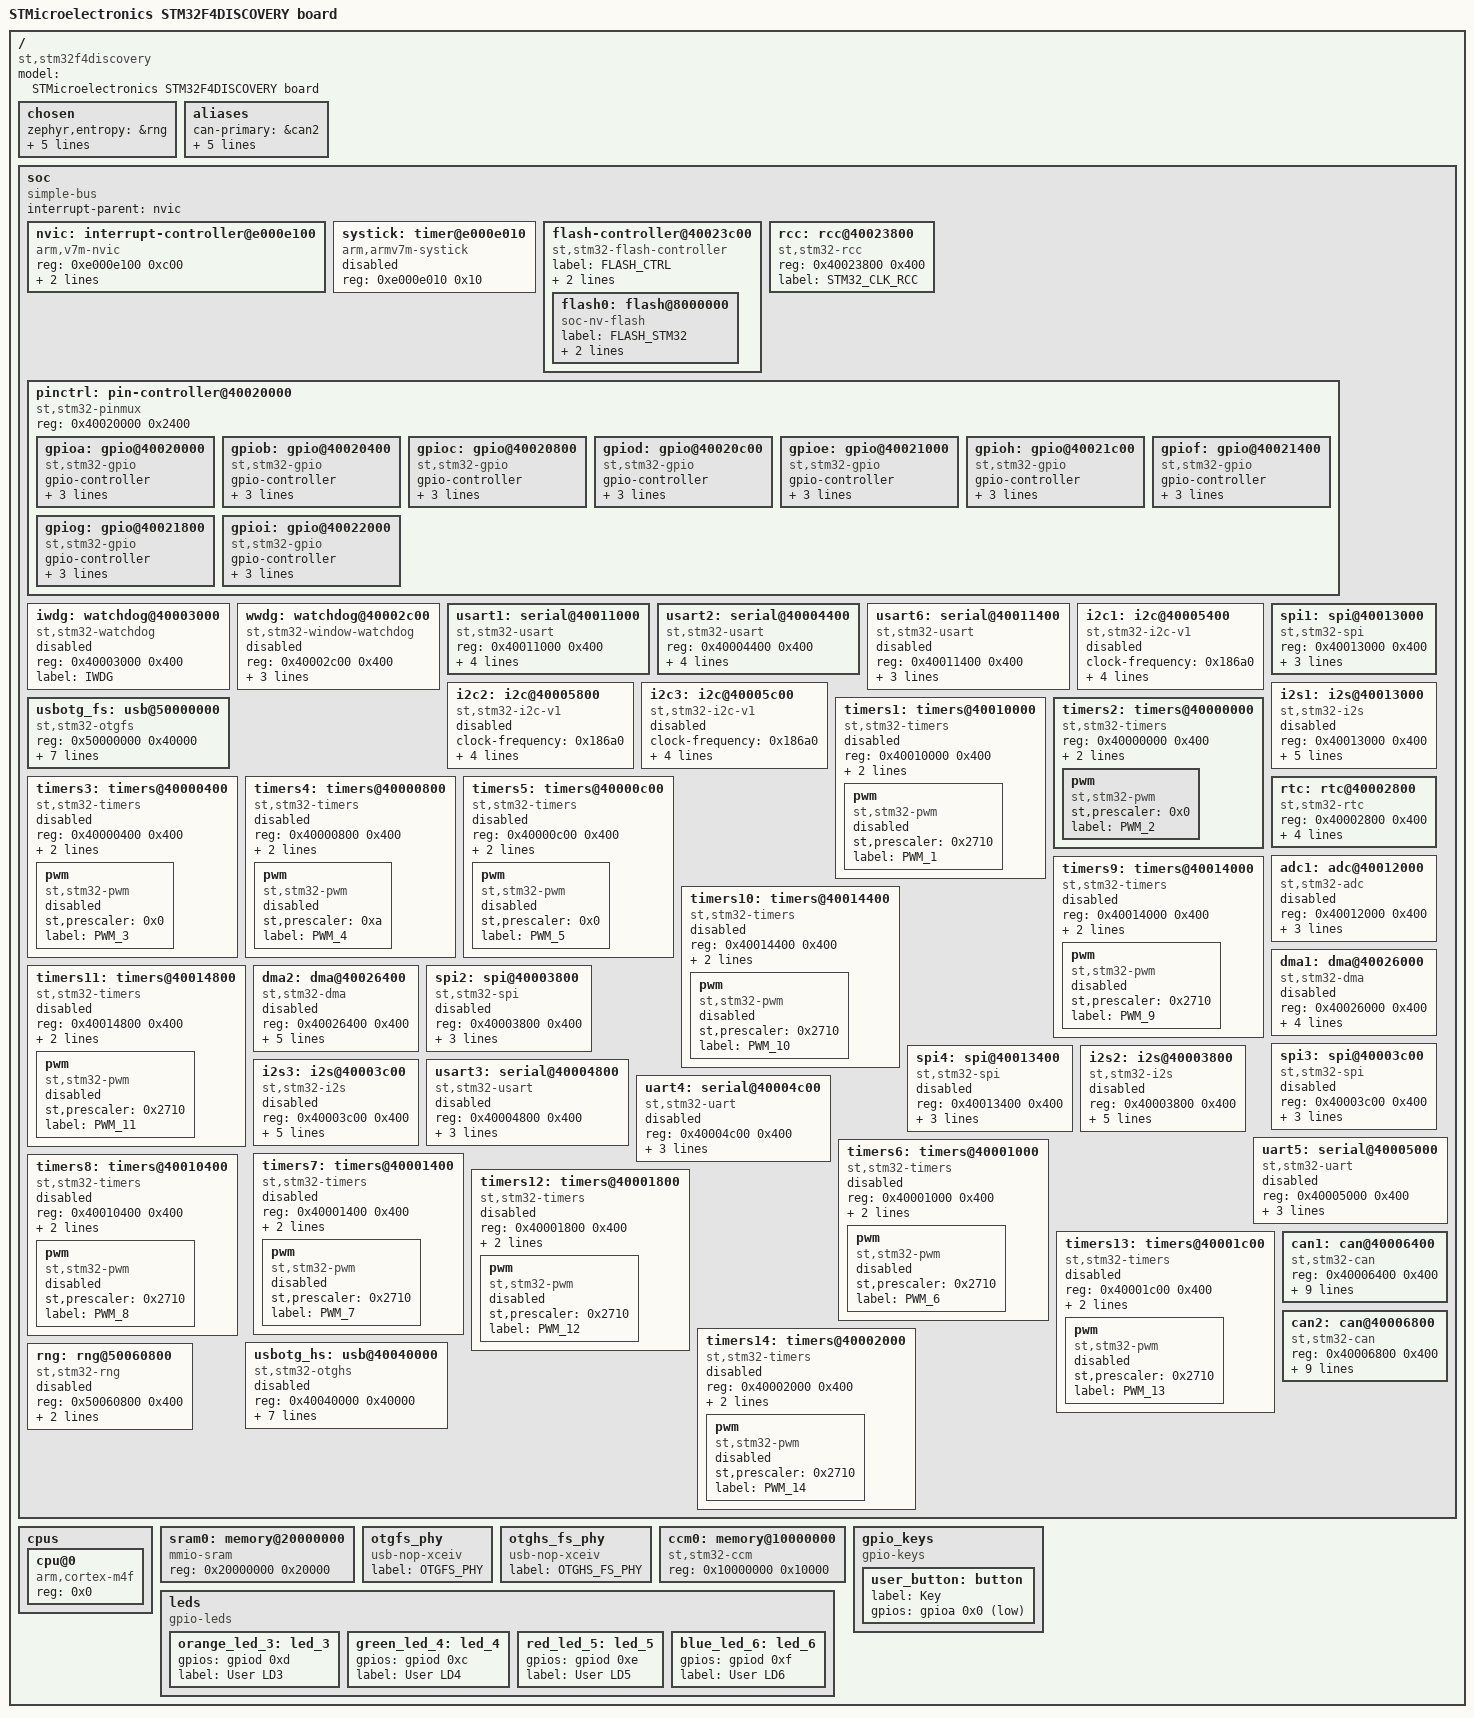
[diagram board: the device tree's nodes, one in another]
/dts-v1/;

/ {
	#address-cells = < 0x1 >;
	#size-cells = < 0x1 >;
	model = "STMicroelectronics STM32F4DISCOVERY board";
	compatible = "st,stm32f4discovery", "st,stm32f407";
	chosen {
		zephyr,entropy = &rng;
		zephyr,console = &usart2;
		zephyr,shell-uart = &usart2;
		zephyr,sram = &sram0;
		zephyr,flash = &flash0;
		zephyr,ccm = &ccm0;
	};
	aliases {
		can-primary = &can2;
		led0 = &green_led_4;
		led1 = &orange_led_3;
		led2 = &red_led_5;
		led3 = &blue_led_6;
		sw0 = &user_button;
	};
	soc {
		#address-cells = < 0x1 >;
		#size-cells = < 0x1 >;
		compatible = "simple-bus";
		interrupt-parent = < &nvic >;
		ranges;
		nvic: interrupt-controller@e000e100 {
			compatible = "arm,v7m-nvic";
			reg = < 0xe000e100 0xc00 >;
			interrupt-controller;
			#interrupt-cells = < 0x2 >;
			arm,num-irq-priority-bits = < 0x4 >;
			phandle = < 0x1 >;
		};
		systick: timer@e000e010 {
			compatible = "arm,armv7m-systick";
			reg = < 0xe000e010 0x10 >;
			status = "disabled";
		};
		flash-controller@40023c00 {
			compatible = "st,stm32-flash-controller", "st,stm32f4-flash-controller";
			label = "FLASH_CTRL";
			reg = < 0x40023c00 0x400 >;
			interrupts = < 0x4 0x0 >;
			#address-cells = < 0x1 >;
			#size-cells = < 0x1 >;
			flash0: flash@8000000 {
				compatible = "soc-nv-flash";
				label = "FLASH_STM32";
				write-block-size = < 0x1 >;
				reg = < 0x8000000 0x100000 >;
			};
		};
		rcc: rcc@40023800 {
			compatible = "st,stm32-rcc";
			#clock-cells = < 0x2 >;
			reg = < 0x40023800 0x400 >;
			label = "STM32_CLK_RCC";
			phandle = < 0x2 >;
		};
		pinctrl: pin-controller@40020000 {
			compatible = "st,stm32-pinmux";
			#address-cells = < 0x1 >;
			#size-cells = < 0x1 >;
			reg = < 0x40020000 0x2400 >;
			gpioa: gpio@40020000 {
				compatible = "st,stm32-gpio";
				gpio-controller;
				#gpio-cells = < 0x2 >;
				reg = < 0x40020000 0x400 >;
				clocks = < &rcc 0x0 0x1 >;
				label = "GPIOA";
				phandle = < 0x8 >;
			};
			gpiob: gpio@40020400 {
				compatible = "st,stm32-gpio";
				gpio-controller;
				#gpio-cells = < 0x2 >;
				reg = < 0x40020400 0x400 >;
				clocks = < &rcc 0x0 0x2 >;
				label = "GPIOB";
			};
			gpioc: gpio@40020800 {
				compatible = "st,stm32-gpio";
				gpio-controller;
				#gpio-cells = < 0x2 >;
				reg = < 0x40020800 0x400 >;
				clocks = < &rcc 0x0 0x4 >;
				label = "GPIOC";
			};
			gpiod: gpio@40020c00 {
				compatible = "st,stm32-gpio";
				gpio-controller;
				#gpio-cells = < 0x2 >;
				reg = < 0x40020c00 0x400 >;
				clocks = < &rcc 0x0 0x8 >;
				label = "GPIOD";
				phandle = < 0x7 >;
			};
			gpioe: gpio@40021000 {
				compatible = "st,stm32-gpio";
				gpio-controller;
				#gpio-cells = < 0x2 >;
				reg = < 0x40021000 0x400 >;
				clocks = < &rcc 0x0 0x10 >;
				label = "GPIOE";
			};
			gpioh: gpio@40021c00 {
				compatible = "st,stm32-gpio";
				gpio-controller;
				#gpio-cells = < 0x2 >;
				reg = < 0x40021c00 0x400 >;
				clocks = < &rcc 0x0 0x80 >;
				label = "GPIOH";
			};
			gpiof: gpio@40021400 {
				compatible = "st,stm32-gpio";
				gpio-controller;
				#gpio-cells = < 0x2 >;
				reg = < 0x40021400 0x400 >;
				clocks = < &rcc 0x0 0x20 >;
				label = "GPIOF";
			};
			gpiog: gpio@40021800 {
				compatible = "st,stm32-gpio";
				gpio-controller;
				#gpio-cells = < 0x2 >;
				reg = < 0x40021800 0x400 >;
				clocks = < &rcc 0x0 0x40 >;
				label = "GPIOG";
			};
			gpioi: gpio@40022000 {
				compatible = "st,stm32-gpio";
				gpio-controller;
				#gpio-cells = < 0x2 >;
				reg = < 0x40022000 0x400 >;
				clocks = < &rcc 0x0 0x100 >;
				label = "GPIOI";
			};
		};
		iwdg: watchdog@40003000 {
			compatible = "st,stm32-watchdog";
			reg = < 0x40003000 0x400 >;
			label = "IWDG";
			status = "disabled";
		};
		wwdg: watchdog@40002c00 {
			compatible = "st,stm32-window-watchdog";
			reg = < 0x40002c00 0x400 >;
			clocks = < &rcc 0x2 0x800 >;
			label = "WWDG";
			interrupts = < 0x0 0x7 >;
			status = "disabled";
		};
		usart1: serial@40011000 {
			compatible = "st,stm32-usart", "st,stm32-uart";
			reg = < 0x40011000 0x400 >;
			clocks = < &rcc 0x3 0x10 >;
			interrupts = < 0x25 0x0 >;
			status = "okay";
			label = "UART_1";
			current-speed = < 0x1c200 >;
		};
		usart2: serial@40004400 {
			compatible = "st,stm32-usart", "st,stm32-uart";
			reg = < 0x40004400 0x400 >;
			clocks = < &rcc 0x2 0x20000 >;
			interrupts = < 0x26 0x0 >;
			status = "okay";
			label = "UART_2";
			current-speed = < 0x1c200 >;
		};
		usart6: serial@40011400 {
			compatible = "st,stm32-usart", "st,stm32-uart";
			reg = < 0x40011400 0x400 >;
			clocks = < &rcc 0x3 0x20 >;
			interrupts = < 0x47 0x0 >;
			status = "disabled";
			label = "UART_6";
		};
		i2c1: i2c@40005400 {
			compatible = "st,stm32-i2c-v1";
			clock-frequency = < 0x186a0 >;
			#address-cells = < 0x1 >;
			#size-cells = < 0x0 >;
			reg = < 0x40005400 0x400 >;
			clocks = < &rcc 0x2 0x200000 >;
			interrupts = < 0x1f 0x0 >, < 0x20 0x0 >;
			interrupt-names = "event", "error";
			status = "disabled";
			label = "I2C_1";
		};
		i2c2: i2c@40005800 {
			compatible = "st,stm32-i2c-v1";
			clock-frequency = < 0x186a0 >;
			#address-cells = < 0x1 >;
			#size-cells = < 0x0 >;
			reg = < 0x40005800 0x400 >;
			clocks = < &rcc 0x2 0x400000 >;
			interrupts = < 0x21 0x0 >, < 0x22 0x0 >;
			interrupt-names = "event", "error";
			status = "disabled";
			label = "I2C_2";
		};
		i2c3: i2c@40005c00 {
			compatible = "st,stm32-i2c-v1";
			clock-frequency = < 0x186a0 >;
			#address-cells = < 0x1 >;
			#size-cells = < 0x0 >;
			reg = < 0x40005c00 0x400 >;
			clocks = < &rcc 0x2 0x800000 >;
			interrupts = < 0x48 0x0 >, < 0x49 0x0 >;
			interrupt-names = "event", "error";
			status = "disabled";
			label = "I2C_3";
		};
		spi1: spi@40013000 {
			compatible = "st,stm32-spi";
			#address-cells = < 0x1 >;
			#size-cells = < 0x0 >;
			reg = < 0x40013000 0x400 >;
			clocks = < &rcc 0x3 0x1000 >;
			interrupts = < 0x23 0x5 >;
			status = "okay";
			label = "SPI_1";
		};
		i2s1: i2s@40013000 {
			compatible = "st,stm32-i2s";
			#address-cells = < 0x1 >;
			#size-cells = < 0x0 >;
			reg = < 0x40013000 0x400 >;
			clocks = < &rcc 0x3 0x1000 >;
			interrupts = < 0x23 0x5 >;
			dmas = < &dma2 0x3 0x3 0x400 0x3 &dma2 0x2 0x3 0x400 0x3 >;
			dma-names = "tx", "rx";
			status = "disabled";
			label = "I2S_1";
		};
		usbotg_fs: usb@50000000 {
			compatible = "st,stm32-otgfs";
			reg = < 0x50000000 0x40000 >;
			interrupts = < 0x43 0x0 >;
			interrupt-names = "otgfs";
			num-bidir-endpoints = < 0x4 >;
			ram-size = < 0x500 >;
			maximum-speed = "full-speed";
			phys = < &otgfs_phy >;
			clocks = < &rcc 0x1 0x80 >;
			status = "okay";
			label = "OTGFS";
		};
		timers1: timers@40010000 {
			compatible = "st,stm32-timers";
			reg = < 0x40010000 0x400 >;
			clocks = < &rcc 0x3 0x1 >;
			status = "disabled";
			label = "TIMERS_1";
			pwm {
				compatible = "st,stm32-pwm";
				status = "disabled";
				st,prescaler = < 0x2710 >;
				label = "PWM_1";
				#pwm-cells = < 0x2 >;
			};
		};
		timers2: timers@40000000 {
			compatible = "st,stm32-timers";
			reg = < 0x40000000 0x400 >;
			clocks = < &rcc 0x2 0x1 >;
			status = "okay";
			label = "TIMERS_2";
			pwm {
				compatible = "st,stm32-pwm";
				status = "okay";
				st,prescaler = < 0x0 >;
				label = "PWM_2";
				#pwm-cells = < 0x2 >;
			};
		};
		timers3: timers@40000400 {
			compatible = "st,stm32-timers";
			reg = < 0x40000400 0x400 >;
			clocks = < &rcc 0x2 0x2 >;
			status = "disabled";
			label = "TIMERS_3";
			pwm {
				compatible = "st,stm32-pwm";
				status = "disabled";
				st,prescaler = < 0x0 >;
				label = "PWM_3";
				#pwm-cells = < 0x2 >;
			};
		};
		timers4: timers@40000800 {
			compatible = "st,stm32-timers";
			reg = < 0x40000800 0x400 >;
			clocks = < &rcc 0x2 0x4 >;
			status = "disabled";
			label = "TIMERS_4";
			pwm {
				compatible = "st,stm32-pwm";
				status = "disabled";
				st,prescaler = < 0xa >;
				label = "PWM_4";
				#pwm-cells = < 0x2 >;
			};
		};
		timers5: timers@40000c00 {
			compatible = "st,stm32-timers";
			reg = < 0x40000c00 0x400 >;
			clocks = < &rcc 0x2 0x8 >;
			status = "disabled";
			label = "TIMERS_5";
			pwm {
				compatible = "st,stm32-pwm";
				status = "disabled";
				st,prescaler = < 0x0 >;
				label = "PWM_5";
				#pwm-cells = < 0x2 >;
			};
		};
		timers9: timers@40014000 {
			compatible = "st,stm32-timers";
			reg = < 0x40014000 0x400 >;
			clocks = < &rcc 0x3 0x10000 >;
			status = "disabled";
			label = "TIMERS_9";
			pwm {
				compatible = "st,stm32-pwm";
				status = "disabled";
				st,prescaler = < 0x2710 >;
				label = "PWM_9";
				#pwm-cells = < 0x2 >;
			};
		};
		timers10: timers@40014400 {
			compatible = "st,stm32-timers";
			reg = < 0x40014400 0x400 >;
			clocks = < &rcc 0x3 0x20000 >;
			status = "disabled";
			label = "TIMERS_10";
			pwm {
				compatible = "st,stm32-pwm";
				status = "disabled";
				st,prescaler = < 0x2710 >;
				label = "PWM_10";
				#pwm-cells = < 0x2 >;
			};
		};
		timers11: timers@40014800 {
			compatible = "st,stm32-timers";
			reg = < 0x40014800 0x400 >;
			clocks = < &rcc 0x3 0x40000 >;
			status = "disabled";
			label = "TIMERS_11";
			pwm {
				compatible = "st,stm32-pwm";
				status = "disabled";
				st,prescaler = < 0x2710 >;
				label = "PWM_11";
				#pwm-cells = < 0x2 >;
			};
		};
		rtc: rtc@40002800 {
			compatible = "st,stm32-rtc";
			reg = < 0x40002800 0x400 >;
			interrupts = < 0x29 0x0 >;
			clocks = < &rcc 0x2 0x10000000 >;
			prescaler = < 0x8000 >;
			status = "okay";
			label = "RTC_0";
		};
		adc1: adc@40012000 {
			compatible = "st,stm32-adc";
			reg = < 0x40012000 0x400 >;
			clocks = < &rcc 0x3 0x100 >;
			interrupts = < 0x12 0x0 >;
			status = "disabled";
			label = "ADC_1";
			#io-channel-cells = < 0x1 >;
		};
		dma1: dma@40026000 {
			compatible = "st,stm32-dma";
			#dma-cells = < 0x4 >;
			reg = < 0x40026000 0x400 >;
			interrupts = < 0xb 0x0 0xc 0x0 0xd 0x0 0xe 0x0 0xf 0x0 0x10 0x0 0x11 0x0 0x2f 0x0 >;
			clocks = < &rcc 0x0 0x200000 >;
			status = "disabled";
			label = "DMA_1";
			phandle = < 0x5 >;
		};
		dma2: dma@40026400 {
			compatible = "st,stm32-dma";
			#dma-cells = < 0x4 >;
			reg = < 0x40026400 0x400 >;
			interrupts = < 0x38 0x0 0x39 0x0 0x3a 0x0 0x3b 0x0 0x3c 0x0 0x44 0x0 0x45 0x0 0x46 0x0 >;
			clocks = < &rcc 0x0 0x400000 >;
			st,mem2mem;
			status = "disabled";
			label = "DMA_2";
			phandle = < 0x3 >;
		};
		spi2: spi@40003800 {
			compatible = "st,stm32-spi";
			#address-cells = < 0x1 >;
			#size-cells = < 0x0 >;
			reg = < 0x40003800 0x400 >;
			clocks = < &rcc 0x2 0x4000 >;
			interrupts = < 0x24 0x5 >;
			status = "disabled";
			label = "SPI_2";
		};
		spi3: spi@40003c00 {
			compatible = "st,stm32-spi";
			#address-cells = < 0x1 >;
			#size-cells = < 0x0 >;
			reg = < 0x40003c00 0x400 >;
			clocks = < &rcc 0x2 0x8000 >;
			interrupts = < 0x33 0x5 >;
			status = "disabled";
			label = "SPI_3";
		};
		spi4: spi@40013400 {
			compatible = "st,stm32-spi";
			#address-cells = < 0x1 >;
			#size-cells = < 0x0 >;
			reg = < 0x40013400 0x400 >;
			clocks = < &rcc 0x3 0x2000 >;
			interrupts = < 0x54 0x5 >;
			status = "disabled";
			label = "SPI_4";
		};
		i2s2: i2s@40003800 {
			compatible = "st,stm32-i2s";
			#address-cells = < 0x1 >;
			#size-cells = < 0x0 >;
			reg = < 0x40003800 0x400 >;
			clocks = < &rcc 0x2 0x4000 >;
			interrupts = < 0x24 0x5 >;
			dmas = < &dma1 0x4 0x0 0x400 0x3 &dma1 0x3 0x0 0x400 0x3 >;
			dma-names = "tx", "rx";
			status = "disabled";
			label = "I2S_2";
		};
		i2s3: i2s@40003c00 {
			compatible = "st,stm32-i2s";
			#address-cells = < 0x1 >;
			#size-cells = < 0x0 >;
			reg = < 0x40003c00 0x400 >;
			clocks = < &rcc 0x2 0x8000 >;
			interrupts = < 0x33 0x5 >;
			dmas = < &dma1 0x5 0x0 0x400 0x3 &dma1 0x0 0x0 0x400 0x3 >;
			dma-names = "tx", "rx";
			status = "disabled";
			label = "I2S_3";
		};
		usart3: serial@40004800 {
			compatible = "st,stm32-usart", "st,stm32-uart";
			reg = < 0x40004800 0x400 >;
			clocks = < &rcc 0x2 0x40000 >;
			interrupts = < 0x27 0x0 >;
			status = "disabled";
			label = "UART_3";
		};
		uart4: serial@40004c00 {
			compatible = "st,stm32-uart";
			reg = < 0x40004c00 0x400 >;
			clocks = < &rcc 0x2 0x80000 >;
			interrupts = < 0x34 0x0 >;
			status = "disabled";
			label = "UART_4";
		};
		uart5: serial@40005000 {
			compatible = "st,stm32-uart";
			reg = < 0x40005000 0x400 >;
			clocks = < &rcc 0x2 0x100000 >;
			interrupts = < 0x35 0x0 >;
			status = "disabled";
			label = "UART_5";
		};
		timers6: timers@40001000 {
			compatible = "st,stm32-timers";
			reg = < 0x40001000 0x400 >;
			clocks = < &rcc 0x2 0x10 >;
			status = "disabled";
			label = "TIMERS_6";
			pwm {
				compatible = "st,stm32-pwm";
				status = "disabled";
				st,prescaler = < 0x2710 >;
				label = "PWM_6";
				#pwm-cells = < 0x2 >;
			};
		};
		timers7: timers@40001400 {
			compatible = "st,stm32-timers";
			reg = < 0x40001400 0x400 >;
			clocks = < &rcc 0x2 0x20 >;
			status = "disabled";
			label = "TIMERS_7";
			pwm {
				compatible = "st,stm32-pwm";
				status = "disabled";
				st,prescaler = < 0x2710 >;
				label = "PWM_7";
				#pwm-cells = < 0x2 >;
			};
		};
		timers8: timers@40010400 {
			compatible = "st,stm32-timers";
			reg = < 0x40010400 0x400 >;
			clocks = < &rcc 0x3 0x2 >;
			status = "disabled";
			label = "TIMERS_8";
			pwm {
				compatible = "st,stm32-pwm";
				status = "disabled";
				st,prescaler = < 0x2710 >;
				label = "PWM_8";
				#pwm-cells = < 0x2 >;
			};
		};
		timers12: timers@40001800 {
			compatible = "st,stm32-timers";
			reg = < 0x40001800 0x400 >;
			clocks = < &rcc 0x2 0x40 >;
			status = "disabled";
			label = "TIMERS_12";
			pwm {
				compatible = "st,stm32-pwm";
				status = "disabled";
				st,prescaler = < 0x2710 >;
				label = "PWM_12";
				#pwm-cells = < 0x2 >;
			};
		};
		timers13: timers@40001c00 {
			compatible = "st,stm32-timers";
			reg = < 0x40001c00 0x400 >;
			clocks = < &rcc 0x2 0x80 >;
			status = "disabled";
			label = "TIMERS_13";
			pwm {
				compatible = "st,stm32-pwm";
				status = "disabled";
				st,prescaler = < 0x2710 >;
				label = "PWM_13";
				#pwm-cells = < 0x2 >;
			};
		};
		timers14: timers@40002000 {
			compatible = "st,stm32-timers";
			reg = < 0x40002000 0x400 >;
			clocks = < &rcc 0x2 0x100 >;
			status = "disabled";
			label = "TIMERS_14";
			pwm {
				compatible = "st,stm32-pwm";
				status = "disabled";
				st,prescaler = < 0x2710 >;
				label = "PWM_14";
				#pwm-cells = < 0x2 >;
			};
		};
		usbotg_hs: usb@40040000 {
			compatible = "st,stm32-otghs";
			reg = < 0x40040000 0x40000 >;
			interrupts = < 0x4d 0x0 >, < 0x4a 0x0 >, < 0x4b 0x0 >;
			interrupt-names = "otghs", "ep1_out", "ep1_in";
			num-bidir-endpoints = < 0x6 >;
			ram-size = < 0x1000 >;
			maximum-speed = "full-speed";
			phys = < &otghs_fs_phy >;
			clocks = < &rcc 0x0 0x20000000 >;
			status = "disabled";
			label = "OTGHS";
		};
		can1: can@40006400 {
			compatible = "st,stm32-can";
			#address-cells = < 0x1 >;
			#size-cells = < 0x0 >;
			reg = < 0x40006400 0x400 >;
			interrupts = < 0x13 0x0 >, < 0x14 0x0 >, < 0x15 0x0 >, < 0x16 0x0 >;
			interrupt-names = "TX", "RX0", "RX1", "SCE";
			clocks = < &rcc 0x2 0x2000000 >;
			status = "okay";
			label = "CAN_1";
			bus-speed = < 0x1e848 >;
			sjw = < 0x1 >;
			prop-seg = < 0x0 >;
			phase-seg1 = < 0x5 >;
			phase-seg2 = < 0x6 >;
		};
		can2: can@40006800 {
			compatible = "st,stm32-can";
			#address-cells = < 0x1 >;
			#size-cells = < 0x0 >;
			reg = < 0x40006800 0x400 >;
			interrupts = < 0x3f 0x0 >, < 0x40 0x0 >, < 0x41 0x0 >, < 0x42 0x0 >;
			interrupt-names = "TX", "RX0", "RX1", "SCE";
			clocks = < &rcc 0x2 0x6000000 >;
			status = "okay";
			label = "CAN_2";
			bus-speed = < 0x1e848 >;
			sjw = < 0x1 >;
			prop-seg = < 0x0 >;
			phase-seg1 = < 0x5 >;
			phase-seg2 = < 0x6 >;
		};
		rng: rng@50060800 {
			compatible = "st,stm32-rng";
			reg = < 0x50060800 0x400 >;
			clocks = < &rcc 0x1 0x40 >;
			status = "disabled";
			label = "RNG";
		};
	};
	cpus {
		#address-cells = < 0x1 >;
		#size-cells = < 0x0 >;
		cpu@0 {
			device_type = "cpu";
			compatible = "arm,cortex-m4f";
			reg = < 0x0 >;
		};
	};
	sram0: memory@20000000 {
		compatible = "mmio-sram";
		reg = < 0x20000000 0x20000 >;
	};
	otgfs_phy: otgfs_phy {
		compatible = "usb-nop-xceiv";
		#phy-cells = < 0x0 >;
		label = "OTGFS_PHY";
		phandle = < 0x4 >;
	};
	otghs_fs_phy: otghs_fs_phy {
		compatible = "usb-nop-xceiv";
		#phy-cells = < 0x0 >;
		label = "OTGHS_FS_PHY";
		phandle = < 0x6 >;
	};
	ccm0: memory@10000000 {
		compatible = "st,stm32-ccm";
		reg = < 0x10000000 0x10000 >;
	};
	leds {
		compatible = "gpio-leds";
		orange_led_3: led_3 {
			gpios = < &gpiod 0xd 0x0 >;
			label = "User LD3";
		};
		green_led_4: led_4 {
			gpios = < &gpiod 0xc 0x0 >;
			label = "User LD4";
		};
		red_led_5: led_5 {
			gpios = < &gpiod 0xe 0x0 >;
			label = "User LD5";
		};
		blue_led_6: led_6 {
			gpios = < &gpiod 0xf 0x0 >;
			label = "User LD6";
		};
	};
	gpio_keys {
		compatible = "gpio-keys";
		user_button: button {
			label = "Key";
			gpios = < &gpioa 0x0 0x1 >;
		};
	};
};
